# ARMv8M-Extended register map
Registers are read-only, no defined reset value unless marked. A register's access mark holds for its fields unless they carry their own. Offsets are from the block's base; [hi:lo] are bit positions; {n}, {i} and the like mark numbered series; 'fields as' and 'values as' point back to an identical list.

## PCI — Implementation defined processor configuration information
Base 0xE001E700
0x00 CFGINFOSEL wo — Processor configuration information selection register selects the configuration information which can then be read back using CFGINFORD
0x04 CFGINFORD — Processor configuration information read data register displays the configuration information that the CFGINFOSEL register selects

## PMC — Implementation defined power mode control
Base 0xE001E300
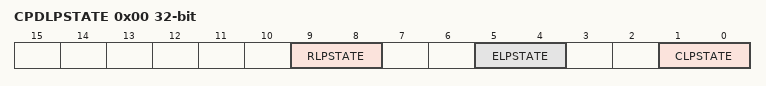
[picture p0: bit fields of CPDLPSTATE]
0x00 CPDLPSTATE rw — Core Power Domain Low Power State Register specifies the desired low-power states for core (PDCORE), Extension Processing Unit (PDEPU), and RAM (PDRAMS) power domains
  [9:8] RLPSTATE — Power-on state for PDRAMS power domain
    0=On; 3=Off
  [5:4] ELPSTATE — Type of low-power state for PDEPU
    0=On; 1=On, but the clock is off; 2=Ret; 3=Off
  [1:0] CLPSTATE — Type of low-power state for PDCORE
    0=On; 1=On, but the clock is off; 2=Ret; 3=Off
0x04 DPDLPSTATE rw — Debug Power Domain Low Power State Register specifies the desired low-power states for the debug (PDDEBUG) power domain
  [1:0] DLPSTATE — Type of low-power state for PDDEBUG
    0=On; 1=On, but the clock is off; 2=Reserved. Treated as ON, but clock OFF.; 3=Off

## SAU — Security Attribution Unit
Base 0xE000EDD0
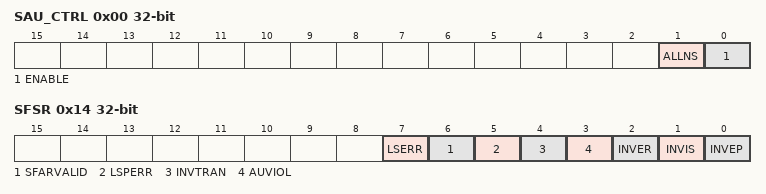
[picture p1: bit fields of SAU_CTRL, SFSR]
0x00 SAU_CTRL rw — Security Attribution Unit Control Register allows enabling of the Security Attribution Unit (SAU)
  [1] ALLNS — When SAU_CTRL.ENABLE is 0 this bit controls whether the memory is marked as Non-secure or Secure
    0=Memory is marked as Secure and is not Non-secure callable; 1=Memory is marked as Non-secure
  [0] ENABLE — Enables the (SAU)
    0=Unit is disabled; 1=Unit is enabled
0x04 SAU_TYPE — Security Attribution Unit Type Register indicates the number of regions implemented by the Security Attribution Unit (SAU)
  [7:0] SREGION — The number of implemented (SAU) regions
0x08 SAU_RNR rw — Security Attribution Unit Region Number Register selects the region currently accessed by SAU_RBAR and SAU_RLAR
  [7:0] REGION — Indicates the Security Attribution Unit (SAU) region accessed by SAU_RBAR and SAU_RLAR
0x0C SAU_RBAR rw — Security Attribution Unit Region Base Address Register provides indirect read and write access to the base address of the currently selected Security Attribution Unit (SAU) region
  [31:5] BADDR — Holds bits[31:5] of the base address for the selected (SAU) region
0x10 SAU_RLAR rw — Security Attribution Unit Region Limit Address Register provides indirect read and write access to the limit address of the currently selected Security Attribution Unit (SAU) region
  [31:5] LADDR — Holds bits[31:5] of the limit address for the selected (SAU) region
  [31:5] NSC — Controls whether Non-secure state is permitted to execute an SG instruction from this region
    0=Region is not Non-secure callable; 1=Region is Non-secure callable
  [31:5] ENABLE — (SAU) region enable
    0=Region is disabled; 1=Region is enabled
0x14 SFSR rw — Secure Fault Status Register provides information about any security related faults
  [7] LSERR — Sticky flag indicating that an error occurred during lazy state activation or deactivation
    0=Error has not occurred; 1=Error has occurred
  [6] SFARVALID — This bit is set when the SFAR register contains a valid value
    0=SFAR content not valid; 1=SFAR content valid
  [5] LSPERR — Sticky flag indicating that an Security Attribution Unit (SAU) or Implementation Defined Attribution Unit (IDAU) violation occurred during the lazy preservation of floating-point state
    0=Error has not occurred; 1=Error has occurred
  [4] INVTRAN — Sticky flag indicating that an exception was raised due to a branch that was not flagged as being domain crossing causing a transition from Secure to Non-secure memory
    0=Error has not occurred; 1=Error has occurred
  [3] AUVIOL — Sticky flag indicating that an attempt was made to access parts of the address space that are marked as Secure with NS-Req for the transaction set to Non-secure
    0=Error has not occurred; 1=Error has occurred
  [2] INVER — Indicates EXC_RETURN.DCRS being set to 0 when returning from an exception in the Non-secure state, or EXC_RETURN.ES being set to 1 when returning from an exception in the Non-secure state
    0=Error has not occurred; 1=Error has occurred
  [1] INVIS — Indicates the integrity signature in an exception stack frame is found to be invalid during the unstacking operation
    0=Error has not occurred; 1=Error has occurred
  [0] INVEP — Inidcates a function call from the Non-secure state or exception targets a non-SG instruction in the Secure state
    0=Error has not occurred; 1=Error has occurred
0x18 SFAR rw — Secure Fault Address Register shows the address of the memory location that caused a security violation

## SYSTICK — SysTick Timer
Base 0xE000E010
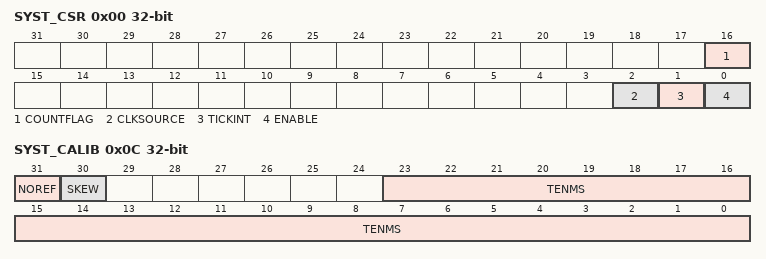
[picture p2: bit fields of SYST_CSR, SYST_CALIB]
0x00 SYST_CSR rw — SysTick Control and Status Register controls and provides status date for the SysTick timer
  [16] COUNTFLAG — Returns 1 if timer counted to 0 since the last read of this register
    0=Timer has not counted to 0; 1=Timer has counted to 0
  [2] CLKSOURCE — Selects the SysTick timer clock source
    0=External reference clock; 1=Processor clock
  [1] TICKINT — Enables SysTick exception request
    0=Counting down to zero does not assert the SysTick exception request; 1=Counting down to zero asserts the SysTick exception request
  [0] ENABLE — Enables the counter
    0=Counter disabled; 1=Counter enabled
0x04 SYST_RVR rw — SysTick Reload Value Register specifies the SysTick timer counter reload value
  [23:0] RELOAD — Value to load into the SYST_CVR when the counter is enabled and when it reaches 0
0x08 SYST_CVR rw — SysTick Current Value Register contains the current value of the SysTick counter
  [23:0] CURRENT — Current value of the SysTick counter. A write of any value clears the field to 0, and also clears the SYST_CSR.COUNTFLAG bit to 0.
0x0C SYST_CALIB — SysTick Calibration value Register indicates the SysTick calibration value and parameters for the selected Security state
  [31] NOREF — Indicates whether the device provides a reference clock to the processor
    0=Reference clock provided; 1=No reference clock provided
  [30] SKEW — Indicates whether the TENMS value is exact
    0=TENMS value is exact; 1=TENMS value is inexact, and has a rounding error of +/- 0.5 of one LSB
  [23:0] TENMS — Reload value for 10ms (100Hz) timing, subject to system clock skew errors. If the value reads as zero, the calibration value is not known.

## TCM_SecGate — TCM Security Gate
Base 0xE001E500
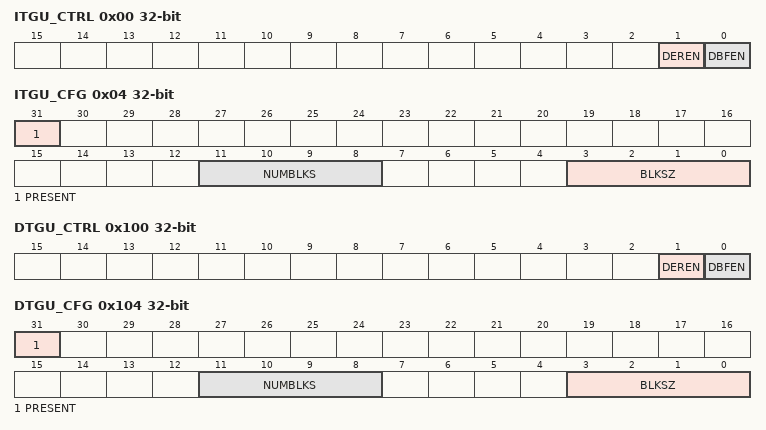
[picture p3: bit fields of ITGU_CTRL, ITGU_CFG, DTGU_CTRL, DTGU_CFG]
0x00 ITGU_CTRL rw — ITGU Control Registers main TCM Gate Unit (TGU) control registers for the ITCM
  [1] DEREN — Enable Slave AHB (S-AHB) error response for TGU fault
    0=Error response not enabled; 1=Error response enabled
  [0] DBFEN — Enable data side BusFault for TGU fault
    0=BusFault not enabled; 1=BusFault enabled
0x04 ITGU_CFG — ITGU Configuration Registers provides access to configuration values for the ITGU
  [31] PRESENT — Determines if the TGU is present
    0=TGU not present; 1=TGU is present
  [11:8] NUMBLKS — This value is used to calculate the number of TCM blocks
  [3:0] BLKSZ — TGU block size in bytes
{0x10+4i} ITGU Look Up Table Registers[{i}] (i=0..15) rw — Identifying the ITGU blocks as being Secure or Non-secure
0x100 DTGU_CTRL rw — DTGU Control Registers main TCM Gate Unit (TGU) control registers for the DTCM
  fields as ITGU_CTRL
0x104 DTGU_CFG — DTGU Configuration Registers provides access to configuration values for the DTGU
  fields as ITGU_CFG
{0x110+4i} DTGU Look Up Table Registers[{i}] (i=0..15) rw — Identifying the DTGU blocks as being Secure or Non-secure
